# PLL0_CFG register map
Vendor: Texas Instruments
Peripheral module from a debugger description file (folder am65x).
Registers are 32-bit, access per field, reset values left out (the file's numbers can be read two ways) unless marked. A register's access mark holds for its fields unless they carry their own. Offsets are as the file gives them; lines under a group give offsets from that group; [hi:lo] are bit positions; {n}, {i} and the like mark numbered series; 'fields as' and 'values as' point back to an identical list; <NAME> marks a mode.

## PLL0_CFG
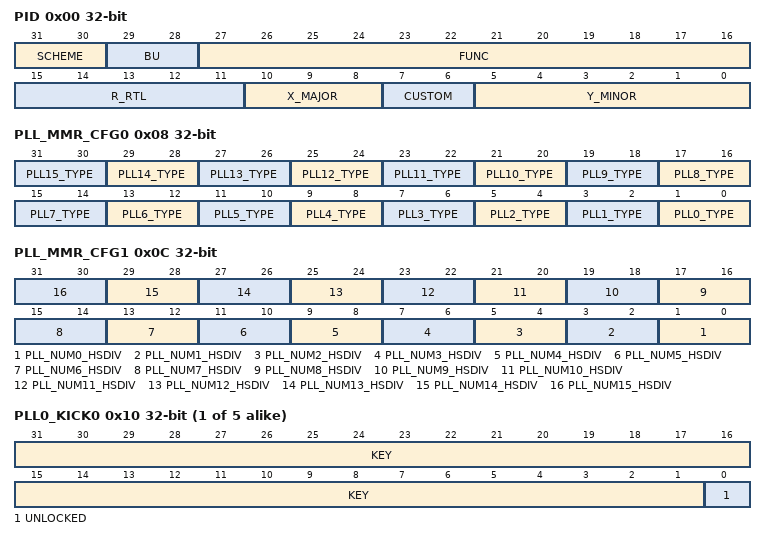
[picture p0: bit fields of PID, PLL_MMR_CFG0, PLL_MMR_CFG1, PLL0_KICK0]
0x00 PID ro — Peripheral release details.
  [31:30] SCHEME
  [29:28] BU — Business unit - Processors
  [27:16] FUNC — Module functional identifier - PLL MMR
  [15:11] R_RTL — RTL revision number - actual value determined by RTL
  [10:8] X_MAJOR — Major revision number - actual value determined by RTL
  [7:6] CUSTOM — Custom revision number - actual value determined by RTL
  [5:0] Y_MINOR — Minor revision number - actual value determined by RTL
0x08 PLL_MMR_CFG0 ro — Indicates the configuration of this set of PLL control registers.
  [2n+1:2n] PLL{n}_TYPE (n=0..15) — Indicates PLL{n} presence and type 0h - PLL is not present 1h - Standard ADPLLM is present 2h - Low-jitter ADPLLLJM is present 3h - Reserved
0x0C PLL_MMR_CFG1 ro — Indicates the configuration of this set of PLL control registers.
  [2n+1:2n] PLL_NUM{n}_HSDIV (n=0..15) — Indicates the number of High Speed dividers used on PLL{n}
{0x10+0x1000*i} PLL{i}_KICK0 (i=0..4) — Lower 32-bits of PLL{i} register write lock key This register must be written with the designated key value followed by a write to with its key value before PLL{i} registers can be written.
  [31:1] KEY rw — Write the kick0 unlock value followed by the kick1 unlock value to unlock the write-protected Partition{i} registers
  [0] UNLOCKED ro — Unlock status.
{0x14+0x1000*i} PLL{i}_KICK1 rw (i=0..4) — Upper 32-bits of PLL{i} register write lock key This register must be written with the designated key value following a write to with its key value before PLL{i} registers can be written.
  [31:0] KEY — Write the kick1 unlock value after the kick0 unlock value to unlock the write-protected Partition{i} registers
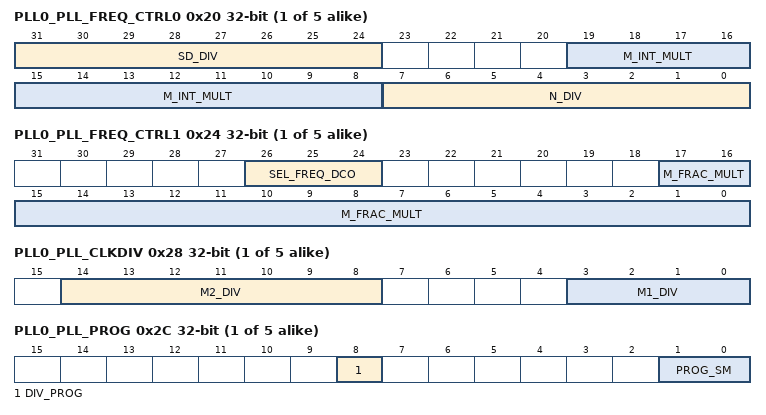
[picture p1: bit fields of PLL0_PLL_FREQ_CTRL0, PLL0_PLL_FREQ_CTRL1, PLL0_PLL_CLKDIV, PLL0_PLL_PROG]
{0x20+0x1000*i} PLL{i}_PLL_FREQ_CTRL0 (i=0..4) — PLL frequency programming values.
  [31:24] SD_DIV rw — Sigma-Delta divider (SD)
  [19:8] M_INT_MULT rw — PLL feedback multiplier (M) integer part
  [7:0] N_DIV rw — PLL Input clock divider (N)
{0x24+0x1000*i} PLL{i}_PLL_FREQ_CTRL1 (i=0..4) — PLL frequency programming values.
  [26:24] SEL_FREQ_DCO rw — DCO frequency range selector 2h - HS2 mode - DCOCLK is 750 to 1500 MHz 4h - HS1 mode - DCOCLK is 1250 to 2500 MHz
  [17:0] M_FRAC_MULT rw — PLL feedback multiplier (M) fractional part
{0x28+0x1000*i} PLL{i}_PLL_CLKDIV (i=0..4) — Divider values for the PLL output clocks.
  [14:8] M2_DIV rw — PLL DCO output divider (M2)
  [3:0] M1_DIV rw — PLL bypass output divider (M1)
{0x2C+0x1000*i} PLL{i}_PLL_PROG (i=0..4) — Drives the signals used to load the PLL frequency configuration values.
  [8] DIV_PROG rw — Output divider load enable
  [1:0] PROG_SM rw — PLL programming state 0h - Activation 1h - Programming IDLE state 2h - Load PLL loop values (PLL_FREQ_CTRL0, PLL_FREQ_CTRL1) 3h - Calibrate and lock
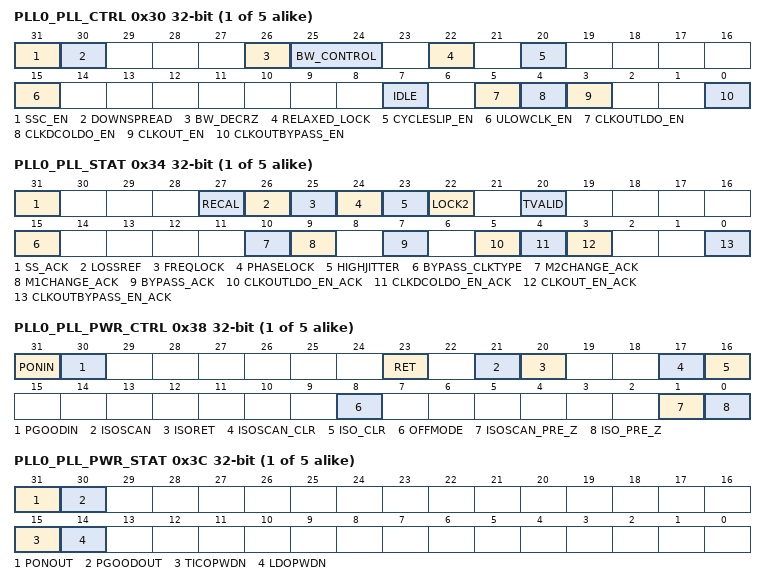
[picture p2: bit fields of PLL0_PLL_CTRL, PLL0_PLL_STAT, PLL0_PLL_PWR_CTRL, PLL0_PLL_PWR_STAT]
{0x30+0x1000*i} PLL{i}_PLL_CTRL (i=0..4) — Controls the PLL features and mode of operation.
  [31] SSC_EN rw — Enable spread spectrum operation
  [30] DOWNSPREAD rw — Spread spectrum clocking spread operation
  [26] BW_DECRZ rw — Decreases loop bandwidth ranges
  [25:24] BW_CONTROL rw — Loop bandwidth control 0h - BW = REFCLK/30 to REFCLK/70 1h - BW = REFCLK/60 to REFCLK/10 2h - BW = REFCLK/120 to REFCLK/280 3h - BW = REFCLK/240 to REFCLK/560
  [22] RELAXED_LOCK rw — Enable relaxed lock mode
  [20] CYCLESLIP_EN rw — Enable recalibration on cycle slip between REFCLK and Feedback clock
  [15] ULOWCLK_EN rw — Bypass mode clock select
  [7] IDLE rw — Set PLL in idle mode
  [5] CLKOUTLDO_EN rw — CLKOUTLDO enable
  [4] CLKDCOLDO_EN rw — CLKDCOLDO enable
  [3] CLKOUT_EN rw — CLKOUT enable
  [0] CLKOUTBYPASS_EN rw — CLKOUTBYPASS enable
{0x34+0x1000*i} PLL{i}_PLL_STAT ro (i=0..4) — Indicates the status of PLL operation.
  [31] SS_ACK — Spread spectrum clocking status
  [27] RECAL — Internal recalibration required
  [26] LOSSREF — Reference input loss indicator
  [25] FREQLOCK — PLL is in frequency lock
  [24] PHASELOCK — PLL is in phase lock
  [23] HIGHJITTER — High jitter status
  [22] LOCK2 — ADPLL internal loop lock status
  [20] TVALID — Valid phase lock indicator
  [15] BYPASS_CLKTYPE — Bypass mode CLK source indicator
  [10] M2CHANGE_ACK — M2 divider change done
  [9] M1CHANGE_ACK — M1 divider change done
  [7] BYPASS_ACK — Bypass status
  [5] CLKOUTLDO_EN_ACK — CLKOUTLDO enable status
  [4] CLKDCOLDO_EN_ACK — CLKDCOLDO enable status
  [3] CLKOUT_EN_ACK — CLKOUT enable status
  [0] CLKOUTBYPASS_EN_ACK — CLKOUTBYPASS enable status
{0x38+0x1000*i} PLL{i}_PLL_PWR_CTRL (i=0..4) — Controls PLL power features.
  [31] PONIN rw — Weak power switch control
  [30] PGOODIN rw — Strong power switch control
  [23] RET rw — Retention mode control (digital)
  [21] ISOSCAN rw — LDO domain testmode scan pin control
  [20] ISORET rw — Output pin isolation control
  [17] ISOSCAN_CLR rw — ISOSCAN latch clear
  [16] ISO_CLR rw — ISORET latch clear
  [8] OFFMODE rw — VDDA logic powerdown
  [1] ISOSCAN_PRE_Z rw — ISOSCAN latch preset
  [0] ISO_PRE_Z rw — ISORET latch preset
{0x3C+0x1000*i} PLL{i}_PLL_PWR_STAT ro (i=0..4) — Indicates the PLL power state.
  [31] PONOUT — Weak power switch status
  [30] PGOODOUT — Strong power switch status
  [15] TICOPWDN — Core DCO power down status
  [14] LDOPWDN — Internal LDO powerdown status
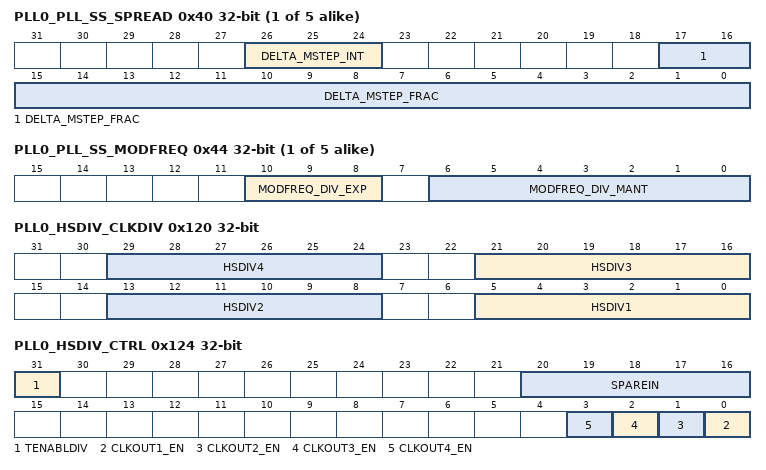
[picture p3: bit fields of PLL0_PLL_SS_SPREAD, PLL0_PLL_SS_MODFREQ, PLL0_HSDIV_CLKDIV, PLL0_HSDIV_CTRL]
{0x40+0x1000*i} PLL{i}_PLL_SS_SPREAD (i=0..4) — Defines the frequency spread when spread spectrum clocking is enabled.
  [26:24] DELTA_MSTEP_INT rw — Spread spectrum spread control integer part
  [17:0] DELTA_MSTEP_FRAC rw — Spread spectrum spread control fractional part
{0x44+0x1000*i} PLL{i}_PLL_SS_MODFREQ (i=0..4) — Defines the modulation frequency when spread spectrum clocking is enabled.
  [10:8] MODFREQ_DIV_EXP rw — Spread spectrum modulation frequency REFCLK divider exponent
  [6:0] MODFREQ_DIV_MANT rw — Spread spectrum modulation frequency REFCLK divider mantissa
0x120 PLL0_HSDIV_CLKDIV — Divider values for the HSDIVIDER output clocks.
  [8n-3:8n-8] HSDIV{n} rw (n=1..4) — CLKOUT{n} divider value
0x124 PLL0_HSDIV_CTRL — Controls the HSDIVIDER features and mode of operation.
  [31] TENABLDIV rw — Output divider load enable
  [20:16] SPAREIN rw — Test mode inputs
  [n-1] CLKOUT{n}_EN rw (n=1..4) — CLKOUT{n} enable
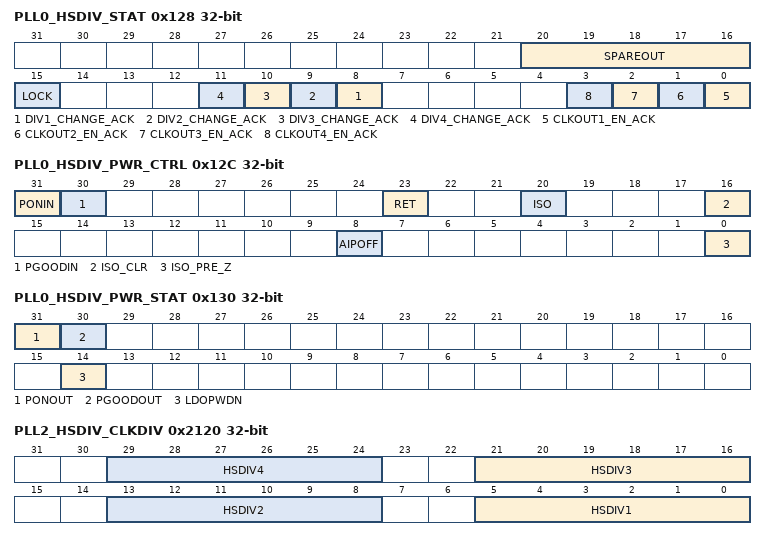
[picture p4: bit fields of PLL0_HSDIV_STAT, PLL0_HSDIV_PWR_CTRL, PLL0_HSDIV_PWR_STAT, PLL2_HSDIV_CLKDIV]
0x128 PLL0_HSDIV_STAT ro — Indicates the status of HSDIVIDER operation.
  [20:16] SPAREOUT — Test outputs
  [15] LOCK — When set, indicates that all enabled output clocks are out of bypass
  [n+7] DIV{n}_CHANGE_ACK (n=1..4) — CLKOUT{n} divider change done
  [n-1] CLKOUT{n}_EN_ACK (n=1..4) — CLKOUT{n} enable status
0x12C PLL0_HSDIV_PWR_CTRL — Controls HSDIVIDER power features.
  [31] PONIN rw — Weak power switch control
  [30] PGOODIN rw — Strong power switch control
  [23] RET rw — Retention mode control (digital)
  [20] ISO rw — Output isolation control
  [16] ISO_CLR rw — ISO latch clear
  [8] AIPOFF rw — Set to 1 to switch off VDDA logic to prevent leakage when VDD power is off and VDDA power is active
  [0] ISO_PRE_Z rw — ISO latch preset (active low)
0x130 PLL0_HSDIV_PWR_STAT ro — Indicates the HSDIVIDER power state.
  [31] PONOUT — Weak power switch status
  [30] PGOODOUT — Strong power switch status
  [14] LDOPWDN — Internal LDO powerdown status
0x2120 PLL2_HSDIV_CLKDIV — Divider values for the HSDIVIDER output clocks.
  [8n-3:8n-8] HSDIV{n} rw (n=1..4) — CLKOUT{n} divider value
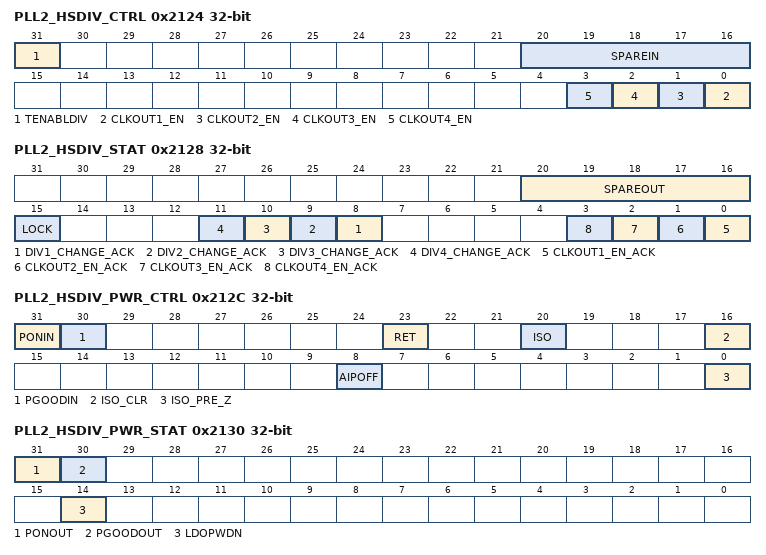
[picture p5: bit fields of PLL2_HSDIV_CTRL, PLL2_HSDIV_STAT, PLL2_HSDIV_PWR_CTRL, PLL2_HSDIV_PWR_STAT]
0x2124 PLL2_HSDIV_CTRL — Controls the HSDIVIDER features and mode of operation.
  fields as PLL0_HSDIV_CTRL
0x2128 PLL2_HSDIV_STAT ro — Indicates the status of HSDIVIDER operation.
  fields as PLL0_HSDIV_STAT
0x212C PLL2_HSDIV_PWR_CTRL — Controls HSDIVIDER power features.
  fields as PLL0_HSDIV_PWR_CTRL
0x2130 PLL2_HSDIV_PWR_STAT ro — Indicates the HSDIVIDER power state.
  fields as PLL0_HSDIV_PWR_STAT
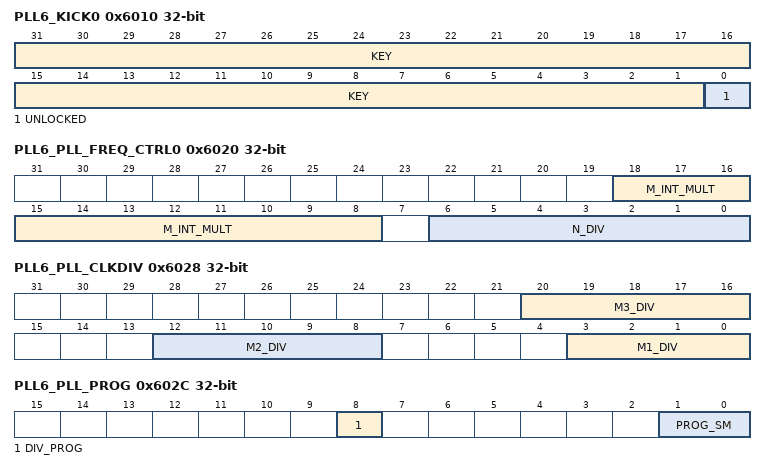
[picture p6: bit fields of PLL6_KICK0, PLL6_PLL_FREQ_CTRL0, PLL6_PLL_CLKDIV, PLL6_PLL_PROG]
0x6010 PLL6_KICK0 — Lower 32-bits of PLL6 register write lock key This register must be written with the designated key value followed by a write to with its key value before PLL6 registers can be written.
  [31:1] KEY rw — Write the kick0 unlock value followed by the kick1 unlock value to unlock the write-protected Partition6 registers
  [0] UNLOCKED ro — Unlock status.
0x6014 PLL6_KICK1 rw — Upper 32-bits of PLL6 register write lock key This register must be written with the designated key value following a write to with its key value before PLL6 registers can be written.
  [31:0] KEY — Write the kick1 unlock value after the kick0 unlock value to unlock the write-protected Partition6 registers
0x6020 PLL6_PLL_FREQ_CTRL0 — PLL frequency programming values.
  [18:8] M_INT_MULT rw — PLL feedback multiplier (M) integer part
  [6:0] N_DIV rw — PLL Input clock divider (N)
0x6024 PLL6_PLL_FREQ_CTRL1 — PLL frequency programming values.
  [17:0] M_FRAC_MULT rw — PLL feedback multiplier (M) fractional part
0x6028 PLL6_PLL_CLKDIV — Divider values for the PLL output clocks.
  [20:16] M3_DIV rw — CLKOUHIF output divider (M3):
  [12:8] M2_DIV rw — PLL DCO output divider (M2)
  [3:0] M1_DIV rw — PLL bypass output divider (M1)
0x602C PLL6_PLL_PROG — Drives the signals used to load the PLL frequency configuration values.
  fields as PLL0_PLL_PROG
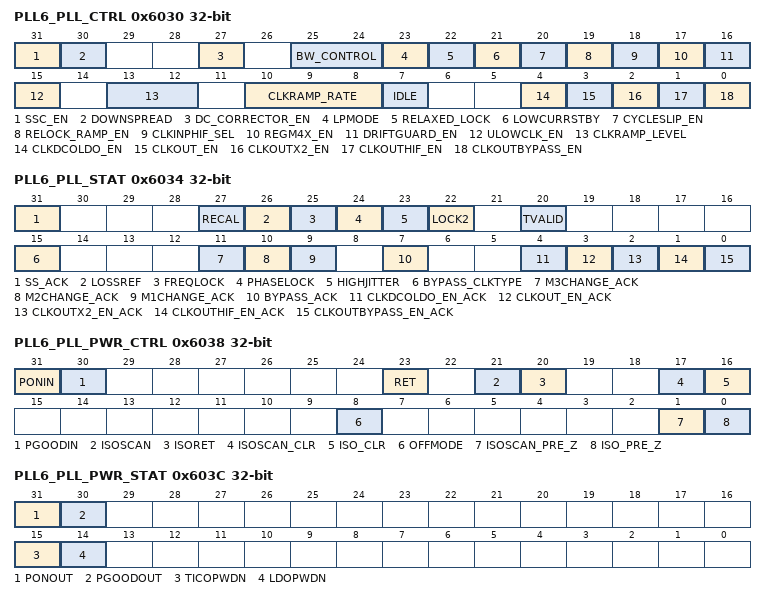
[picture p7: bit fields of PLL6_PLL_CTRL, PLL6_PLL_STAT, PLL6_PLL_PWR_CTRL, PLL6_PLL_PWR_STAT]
0x6030 PLL6_PLL_CTRL — Controls the PLL features and mode of operation.
  [31] SSC_EN rw — Enable spread spectrum operation
  [30] DOWNSPREAD rw — Spread spectrum clocking spread operation
  [27] DC_CORRECTOR_EN rw — Must be set to 1 when CLKOUT &gt; 1.4 GHz is required
  [25:24] BW_CONTROL rw — Loop bandwidth control 0h - BW = REFCLK/30 to REFCLK/70 1h - BW = REFCLK/60 to REFCLK/10 2h - BW = REFCLK/120 to REFCLK/280 3h - BW = REFCLK/240 to REFCLK/560
  [23] LPMODE rw — Low power mode enable
  [22] RELAXED_LOCK rw — Enable relaxed lock mode
  [21] LOWCURRSTBY rw — IDLE/LOSSCLK relock control
  [20] CYCLESLIP_EN rw — Enable recalibration on cycle slip between REFCLK and Feedback clock
  [19] RELOCK_RAMP_EN rw — Relock clock ramp enable
  [18] CLKINPHIF_SEL rw — CLKOUTHIF clock source select
  [17] REGM4X_EN rw — Enable 4x REGM mode
  [16] DRIFTGUARD_EN rw — Re-calibration enable
  [15] ULOWCLK_EN rw — Bypass mode clock select
  [13:12] CLKRAMP_LEVEL rw — Controls the clock ramp sequence 0h - No ramping 1h - Bypass clock to Fout/8 to Fout/4 to Fout/2 to Fout 2h - Bypass clock to Fout/4 to Fout/2 to Fout/1.5 to Fout 3h - Reserved - no ramping
  [10:8] CLKRAMP_RATE rw — Controls the time spent on each ramp step 0h - 2 REFCLK periods 1h - 4 REFCLK periods 2h - 8 REFCLK periods 3h - 16 REFCLK periods 4h - 32 REFCLK periods 5h - 64 REFCLK periods 6h - 128 REFCLK periods 7h - 256 REFCLK periods
  [7] IDLE rw — Set PLL in idle mode
  [4] CLKDCOLDO_EN rw — CLKDCOLDO enable
  [3] CLKOUT_EN rw — CLKOUT enable
  [2] CLKOUTX2_EN rw — CLKOUTX2 enable
  [1] CLKOUTHIF_EN rw — CLKOUTHIF enable
  [0] CLKOUTBYPASS_EN rw — CLKOUTBYPASS enable
0x6034 PLL6_PLL_STAT ro — Indicates the status of PLL operation.
  [31] SS_ACK — Spread spectrum clocking status
  [27] RECAL — Internal recalibration required
  [26] LOSSREF — Reference input loss indicator
  [25] FREQLOCK — PLL is in frequency lock
  [24] PHASELOCK — PLL is in phase lock
  [23] HIGHJITTER — High jitter status
  [22] LOCK2 — ADPLL internal loop lock status
  [20] TVALID — Valid phase lock indicator
  [15] BYPASS_CLKTYPE — Bypass mode CLK source indicator
  [11] M3CHANGE_ACK — M3 divider change done
  [10] M2CHANGE_ACK — M2 divider change done
  [9] M1CHANGE_ACK — M1 divider change done
  [7] BYPASS_ACK — Bypass status
  [4] CLKDCOLDO_EN_ACK — CLKDCOLDO enable status
  [3] CLKOUT_EN_ACK — CLKOUT enable status
  [2] CLKOUTX2_EN_ACK — CLKOUTX2 enable status
  [1] CLKOUTHIF_EN_ACK — CLKOUTHIF enable status
  [0] CLKOUTBYPASS_EN_ACK — CLKOUTBYPASS enable status
0x6038 PLL6_PLL_PWR_CTRL — Controls PLL power features.
  fields as PLL0_PLL_PWR_CTRL
0x603C PLL6_PLL_PWR_STAT ro — Indicates the PLL power state.
  fields as PLL0_PLL_PWR_STAT
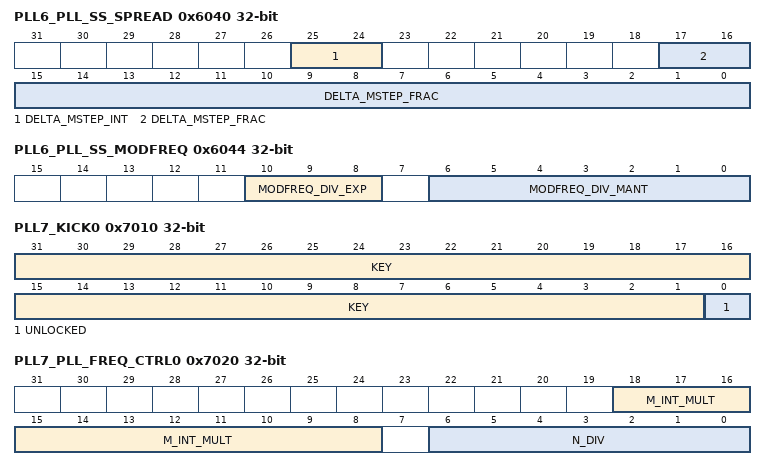
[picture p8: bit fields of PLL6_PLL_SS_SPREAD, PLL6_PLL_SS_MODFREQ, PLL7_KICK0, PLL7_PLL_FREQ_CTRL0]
0x6040 PLL6_PLL_SS_SPREAD — Defines the frequency spread when spread spectrum clocking is enabled.
  [25:24] DELTA_MSTEP_INT rw — Spread spectrum spread control integer part
  [17:0] DELTA_MSTEP_FRAC rw — Spread spectrum spread control fractional part
0x6044 PLL6_PLL_SS_MODFREQ — Defines the modulation frequency when spread spectrum clocking is enabled.
  fields as PLL0_PLL_SS_MODFREQ
0x7010 PLL7_KICK0 — Lower 32-bits of PLL7 register write lock key This register must be written with the designated key value followed by a write to with its key value before PLL7 registers can be written.
  [31:1] KEY rw — Write the kick0 unlock value followed by the kick1 unlock value to unlock the write-protected Partition7 registers
  [0] UNLOCKED ro — Unlock status.
0x7014 PLL7_KICK1 rw — Upper 32-bits of PLL7 register write lock key This register must be written with the designated key value following a write to with its key value before PLL7 registers can be written.
  [31:0] KEY — Write the kick1 unlock value after the kick0 unlock value to unlock the write-protected Partition7 registers
0x7020 PLL7_PLL_FREQ_CTRL0 — PLL frequency programming values.
  fields as PLL6_PLL_FREQ_CTRL0
0x7024 PLL7_PLL_FREQ_CTRL1 — PLL frequency programming values.
  [17:0] M_FRAC_MULT rw — PLL feedback multiplier (M) fractional part
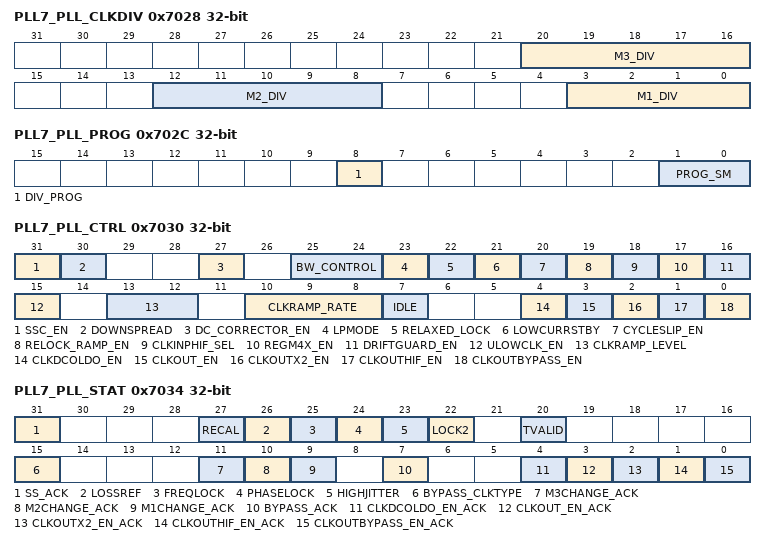
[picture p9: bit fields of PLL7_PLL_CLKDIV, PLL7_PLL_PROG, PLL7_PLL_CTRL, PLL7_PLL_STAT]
0x7028 PLL7_PLL_CLKDIV — Divider values for the PLL output clocks.
  fields as PLL6_PLL_CLKDIV
0x702C PLL7_PLL_PROG — Drives the signals used to load the PLL frequency configuration values.
  fields as PLL0_PLL_PROG
0x7030 PLL7_PLL_CTRL — Controls the PLL features and mode of operation.
  fields as PLL6_PLL_CTRL
0x7034 PLL7_PLL_STAT ro — Indicates the status of PLL operation.
  fields as PLL6_PLL_STAT
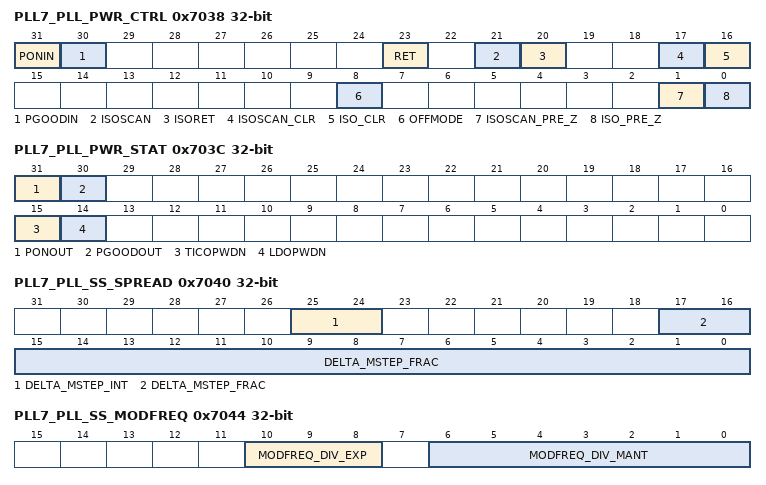
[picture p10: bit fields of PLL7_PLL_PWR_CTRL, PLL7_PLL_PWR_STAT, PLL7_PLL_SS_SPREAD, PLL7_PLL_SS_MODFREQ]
0x7038 PLL7_PLL_PWR_CTRL — Controls PLL power features.
  fields as PLL0_PLL_PWR_CTRL
0x703C PLL7_PLL_PWR_STAT ro — Indicates the PLL power state.
  fields as PLL0_PLL_PWR_STAT
0x7040 PLL7_PLL_SS_SPREAD — Defines the frequency spread when spread spectrum clocking is enabled.
  fields as PLL6_PLL_SS_SPREAD
0x7044 PLL7_PLL_SS_MODFREQ — Defines the modulation frequency when spread spectrum clocking is enabled.
  fields as PLL0_PLL_SS_MODFREQ
